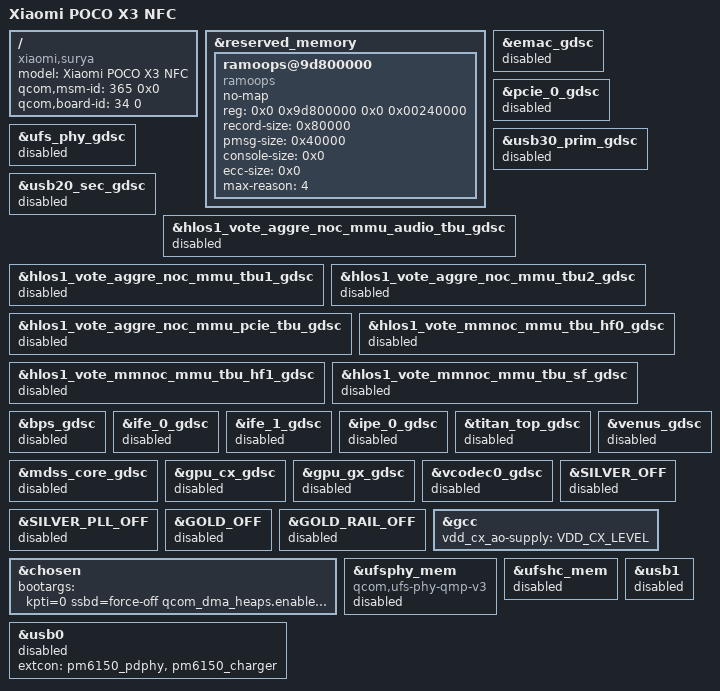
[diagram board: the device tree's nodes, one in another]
// SPDX-License-Identifier: GPL-2.0-only
/dts-v1/;

#include "sm6150.dtsi"
#include "surya-pinctrl.dtsi"
#include "surya-pm6150.dtsi"
#include "surya-display.dtsi"
#include "surya-touch.dtsi"
#include "surya-haptics.dtsi"
#include "surya-nfc.dtsi"

/* Bring-up stub only. Do not flash: inherited platform data is unvalidated. */
/ {
	model = "Xiaomi POCO X3 NFC";
	compatible = "xiaomi,surya", "qcom,sm6150";

	/* IDs from the 4.14 sdmmagpie-idp-overlay-miui.dts. */
	qcom,msm-id = <365 0x0>;
	qcom,board-id = <34 0>;
};

&reserved_memory {
	/*
	 * pstore geometry, derived from what the two kernels that touch this
	 * region actually do -- not guessed.
	 *
	 * Stock 4.14 (arch/arm64/boot/dts/qcom/sdmmagpie.dtsi:669, the DT the
	 * recovery inherits) declares reg = <0x9d800000 0x400000>, record-size
	 * 0x80000, pmsg-size 0x200000, console-size 0x100000, ecc-size 0x10.
	 * Both the 4.14 and the 6.1 ramoops driver lay przs out in one fixed
	 * order -- dmesg, console, ftrace, pmsg -- and give the dmesg set the
	 * whole leftover:
	 *
	 *	dump_mem_sz = mem_size - console - ftrace - pmsg
	 *	cnt         = dump_mem_sz / record-size
	 *	zone_sz     = dump_mem_sz / cnt		(align_down 2)
	 *
	 * so stock resolves to dmesg przs at 0x9d800000 and 0x9d880000 (0x80000
	 * each), console at 0x9d900000, pmsg at 0x9da00000.  The capture lives or
	 * dies on that map, because the recovery reads it and 4.14 destroys what
	 * it does not like (fs/pstore/ram_core.c of that kernel):
	 *
	 *	if (buffer_size(prz) > prz->buffer_size ||
	 *	    buffer_start(prz) > buffer_size(prz))
	 *			pr_info("found existing invalid buffer, ...");
	 *	...
	 *	prz->buffer->sig = sig;
	 *	persistent_ram_zap(prz);		-- the log is gone --
	 *
	 * which is verbatim the report this round: "found existing invalid buffer,
	 * size 57821, start 192977" next to an empty /sys/fs/pstore.
	 *
	 * So the boot console's zone -- 0x9da00000, from
	 * earlycon=ramoops,0x9da00000,0x40000 -- is made the *pmsg* prz, and the
	 * console prz is switched off entirely (console-size 0).  Both halves of
	 * that choice are forced by capture 14 (2026-11-28, console-ramoops-14.txt,
	 * 14225 bytes):
	 *
	 *   1. The same 6.1 kernel boots twice -- once as the kernel under test,
	 *      once as the TWRP kernel that reads the log back.  As a pstore
	 *      *console* owner it logs, 0.227 s into the reading boot:
	 *	[    0.227028] pstore: using zlib compression
	 *	[    0.227539] console [pstore0] enabled
	 *	[    0.227610] ramoops: attached 0x400000@0x9d800000, ecc: 0/0
	 *      (twrp-current-dmesg-9.txt:152-155).  Registering pstore0 untethers
	 *      our earlycon, so the log of the boot under test stops at ~0.227 s;
	 *      and every record the reading boot writes afterwards goes into the
	 *      prz whose header our earlycon owns, rotating the ring we came to
	 *      read.  That is why capture 14 is neither text nor one DEFLATE
	 *      stream: brute-force inflate at every offset (wbits 15/-15/9/-9)
	 *      yields at most 103 bytes of filler, strings -n 14 finds no line,
	 *      and the printable ratio is a flat 38 % from start to end.  A
	 *      capture of somebody else's compressed records, not a silent boot.
	 *   2. The pmsg prz is the only one this driver never writes on its own
	 *      -- /dev/pmsg0 from userspace is its only producer, and recovery
	 *      init never opens it -- so the ring stays exactly as the earlycon
	 *      left it, and both reader families export it (pmsg-ramoops-0, and
	 *      the recovery's own pstore-rw tool).  Earlier rounds already prove
	 *      the path works: pstore-mount-3/4.txt show pmsg-ramoops-0 at 23467
	 *      and 187743 readable bytes while console-ramoops-0 in the same
	 *      directory held 234520 bytes of the *reader's* own log.
	 *
	 * console-size 0 also removes the risk that started this: with two
	 * owners of one 12-byte header, each clamps "size" to its own maximum and
	 * the pair reads start > size -- 192977 is a start the earlycon can never
	 * produce -- and the reader zap()s a zone it calls invalid instead of
	 * exporting it.
	 *
	 * The geometry is unchanged by this, which is the point: solving the two
	 * formulas for a 0x40000 pmsg prz at the end of reg gives mem_size
	 * 0x240000, cnt 4, zone_sz 0x80000, so the dmesg przs still occupy
	 * 0x9d800000..0x9da00000, the pmsg prz is 0x9da00000..0x9da40000 = the
	 * end of reg = the earlycon target, and record-size 0x80000 keeps every
	 * dmesg prz at the size the recovery expects for its own, so a panic
	 * record (dmesg-ramoops-N, deflate, decompressed by this same kernel on
	 * read) survives too.
	 *
	 * ecc-size 0 as well: prz->buffer_size is zone - 12 - ecc
	 * (fs/pstore/ram_core.c:523) while earlycon-ramoops.c uses zone - 12, so
	 * the two owners of one header only agree on capacity without ECC -- and
	 * the reader in the recovery has none either, which its own boot line
	 * states: "ramoops: attached 0x400000@0x9d800000, ecc: 0/0".
	 *
	 * no-map, like the other no-cache regions in this node: a cached alias of
	 * a zone written through ioremap() is a capture that can read back stale.
	 */
	ramoops@9d800000 {
		compatible = "ramoops";
		no-map;
		reg = <0x0 0x9d800000 0x0 0x00240000>;
		record-size = <0x80000>;
		pmsg-size = <0x40000>;
		console-size = <0x0>;
		ecc-size = <0x0>;
		max-reason = <4>;
	};
};

/*
 * The shared SM6150 DT instantiates the 4.14-style vendor gdsc-regulator
 * devices under /soc, but that driver ioremaps the DT reg verbatim while
 * these nodes carry GCC-relative offsets (0x177004 etc.) — so every probe
 * pokes a dead window beside the GCC block.  The first complete boot log
 * (2026-11-27, build 5f716c31f) shows the resulting asynchronous SError
 * landing inside gdsc_probe at 0.33s: readl -> arm_serror_panic -> Kernel
 * panic.  The upstream boot path needs none of them: the 6.1 clock driver
 * owns GDSCs through its C tables, the UFS GDSC is left enabled by the
 * bootloaders exactly as on the stock 4.14 firmware, and the TBU vote
 * nodes have no 6.1 consumer.  Disable the whole family (Violet's own
 * device trees never instantiate it with this driver).
 */
&emac_gdsc { status = "disabled"; };
&pcie_0_gdsc { status = "disabled"; };
&ufs_phy_gdsc { status = "disabled"; };
&usb30_prim_gdsc { status = "disabled"; };
&usb20_sec_gdsc { status = "disabled"; };
&hlos1_vote_aggre_noc_mmu_audio_tbu_gdsc { status = "disabled"; };
&hlos1_vote_aggre_noc_mmu_tbu1_gdsc { status = "disabled"; };
&hlos1_vote_aggre_noc_mmu_tbu2_gdsc { status = "disabled"; };
&hlos1_vote_aggre_noc_mmu_pcie_tbu_gdsc { status = "disabled"; };
&hlos1_vote_mmnoc_mmu_tbu_hf0_gdsc { status = "disabled"; };
&hlos1_vote_mmnoc_mmu_tbu_hf1_gdsc { status = "disabled"; };
&hlos1_vote_mmnoc_mmu_tbu_sf_gdsc { status = "disabled"; };
&bps_gdsc { status = "disabled"; };
&ife_0_gdsc { status = "disabled"; };
&ife_1_gdsc { status = "disabled"; };
&ipe_0_gdsc { status = "disabled"; };
&titan_top_gdsc { status = "disabled"; };
&mdss_core_gdsc { status = "disabled"; };
&gpu_cx_gdsc { status = "disabled"; };
&gpu_gx_gdsc { status = "disabled"; };
&vcodec0_gdsc { status = "disabled"; };
&venus_gdsc { status = "disabled"; };

/*
 * CPU idle states.  This board ships a downstream (4.14-era) PSCI
 * implementation that refuses the OSI-mode switch -- "psci: failed to set PC
 * mode: -3" in every Surya capture -- and has no mapping for the state IDs the
 * inherited DT votes (0x40000003 "pc", 0x40000004 "rail-pc").  The 2026-11-27
 * 20:46 capture shows what that costs: CPU#7 stopped answering IPIs around the
 * first idle entry (~2s), so kick_all_cpus_sync() from the jump-label update
 * spun forever in smp_call_function_many_cond(), RCU never finished a grace
 * period, and init never ran.  Disabling the four CPU states leaves
 * cpuidle-psci with only the WFI state (drivers/cpuidle/dt_idle_states.c skips
 * unavailable states and cpuidle-psci.c adds WFI unconditionally), which is the
 * same idle the stock 4.14 kernel uses until its lpm-levels driver binds.
 * The cluster domain states stay described for the runtime-PM path but are
 * never entered, because no CPU state asks for a cluster power down.
 */
&SILVER_OFF { status = "disabled"; };
&SILVER_PLL_OFF { status = "disabled"; };
&GOLD_OFF { status = "disabled"; };
&GOLD_RAIL_OFF { status = "disabled"; };

/*
 * Boot arguments.  sm6150.dtsi ships fw_devlink.strict=1, which makes every
 * property that lists a phandle a mandatory probe dependency -- including the
 * ones whose supplier is a class device with no driver of its own (see the
 * UFS note below).  fw_devlink=permissive keeps the ordering hints but stops
 * deferring probes on suppliers that can never report "probed", which is how a
 * device tree whose suppliers are class devices (not bound platform drivers) is
 * booted.  loglevel=8 stays because the Surya bring-up markers print at
 * KERN_DEBUG/KERN_NOTICE: at loglevel=7 (the 2026-11-28 21:40 capture) the
 * whole deferral story and the storage snapshot lines were invisible.
 *
 * initcall_debug=1 is dropped as of capture 11.  It is what the last four
 * captures were mined for -- its "probe of af00000.clock-controller returned 0
 * after 6822 usecs" is how dispcc became the control case for GCC -- but one
 * line per initcall and per probe attempt is ~1500 lines, and the 2 MiB
 * console prz then wraps mid-boot: capture 11 came back with two boots
 * byte-interleaved, so the GCC evidence had to be reconstructed instead of
 * read.  gcc_sm6150_probe() now prints one short stage line per step of its
 * own, which is what survives a wrapped buffer, and tools/surya-anykernel no
 *
 * clk_ignore_unused is here because of capture 13, and it is a behaviour knob,
 * not a logging one.  The 6.1 clock framework runs clk_disable_unused() at
 * late_initcall and gates every clock that no driver has claimed, which the
 * downstream 4.14 driver never does: instead of relying on the framework it
 * lists gcc_camera_{ahb,xo}_clk, gcc_disp_{ahb,xo}_clk, gcc_video_{ahb,xo}_clk,
 * gcc_gpu_cfg_ahb_clk, gcc_cpuss_ahb_clk, gcc_cpuss_gnoc_clk and
 * gcc_sys_noc_cpuss_ahb_clk as "critical" and enables them itself
 * (qcom_cc_enable_critical_clks()).  This tree lost that list and kept only the
 * SM8150 register writes that served the same purpose on that SoC -- so by the
 * time the deferred pass reached gcc_sm6150_probe() the AHB path in front of the
 * GCC MISC registers was already gated, and the read that
 * regmap_update_bits(regmap, GCC_CAMERA_MISC, ...) performs first never
 * returned.  Ignoring the unused-clock pass reproduces the 4.14 state for every
 * clock the bootloaders left on, which is the whole point of bring-up here; it
 * also covers the display, camera and GPU register spaces for the same price.
 *
 * softlockup_panic=1 is what makes a capture exist at all.  The detector is
 * already built (CONFIG_SOFTLOCKUP_DETECTOR=y from gki_defconfig) but a report
 * it prints does not stop the boot, so on the boards where a CPU is wedged in a
 * device access init's own 10 s block-device timeout rebooted the phone a few
 * seconds later and the trace either landed in the wrapped tail of the prz or
 * not at all.  With panic the reboot is the *panic* reboot -- warm, so DDR
 * survives -- the buffer ends with "BUG: soft lockup - CPU#N stuck for 22s!"
 * plus that CPU's backtrace, and the collector reads it after.  It also fixes
 * the failure mode seen on 2026-11-28 23:5x, where the boot hung somewhere
 * with no panic and no reboot at all, the user held the power key, and a hard
 * reset drops DDR: /sys/fs/pstore came back empty and the round was lost.
 */
&chosen {
	bootargs = "kpti=0 ssbd=force-off qcom_dma_heaps.enable_bitstream_contig_heap=y rcupdate.rcu_expedited=0 cpufreq.default_governor=performance fw_devlink=permissive cpuidle.off=1 loglevel=8 clk_ignore_unused softlockup_panic=1";
};

/*
 * GCC's CX voltage class.  This is the line that decides whether /soc/ufshc
 * ever probes, and capture 10 (2026-11-28 22:0x, console-ramoops-10.txt)
 * pins it exactly:
 *
 *   1.257457 Surya bringup: r0 probing /soc/clock-controller@100000
 *   1.257865 k61probe: 100000.clock-controller (gcc-sm6150)
 *   ... nothing, ever.  No "Registered GCC clocks", and no
 *   "Rate ... is greater than highest Fmax" line either, so the probe never
 *   reached qcom_cc_really_probe().
 *   5.347050 Surya bringup: provider chain still at /soc/clock-controller@100000
 *   21.475038 Surya bringup: deferred probe still in clock-controller@100000
 *   21.475181 task:kworker/u16:0 state:D ... __mutex_lock+0x408 __device_attach
 *
 * i.e. gcc_sm6150_probe() blocks with the device mutex held, and the serial
 * deferred pass queues behind it.  Before this capture the same probe never
 * even appeared to start, which is why the deferred-probe list looked empty.
 *
 * What it blocks on is the regulator graph, and the DT says why only GCC does:
 * gcc_sm6150_probe() (drivers/clk/qcom/gcc-sm6150.c:3488) makes three
 * mandatory devm_regulator_get() calls and returns the error of each, so an
 * unresolved rail is a probe that cannot finish.  In sm6150-regulator.dtsi the
 * three targets are not peers:
 *
 *   vdd_mx-supply    -> regulator-pm6150-s3           (leaf: no vin/parent edge)
 *   vdd_cx-supply    -> regulator-pm6150-s1          (parent-supply -> s3)
 *   vdd_cx_ao-supply -> regulator-pm6150-s1-level-ao (vin-supply -> s3-level-ao)
 *
 * The AO pair is the odd one out.  Its supplier is the MX AO arc child, whose
 * parent block rpmh-regulator-mxlvl carries no proxy-supply at all (only cxlvl
 * does, which is why the log reports the "Fixed dependency cycle(s)" notice for
 * cxlvl and the VRM LDOs but not for mxlvl), and no driver in this tree except
 * GCC asks for a vdd_cx_ao rail.  dispcc asks for vdd_cx only and its probe
 * returned in 6822 usecs in the same window -- that is the control case: same
 * regulator class, same ARC parent, one supply less, no stall.
 *
 * Capture 11 (2026-11-28) says this was necessary and not sufficient: the
 * property is in the flashed DTB, all three supplies now resolve, and
 * gcc_sm6150_probe() still never returns.  What it is still waiting on is
 * that the regulator *devices* behind these phandles are children of
 * rpmh-regulator-cxlvl/mxlvl and get bound only by the serial deferred pass,
 * which is the pass GCC blocks -- see drivers/base/dd.c, where the chain now
 * names those children explicitly.  This retarget stays because it removes an
 * edge (CX AO to the MX AO arc child) that no other consumer in the tree
 * resolves and that the AO vote does not need on a board that cannot idle.
 *
 * So the AO edge goes away for this board: vote the CX always-on class through
 * the same resolvable pm6150_s1_level regulator the non-AO class uses.  For a
 * level vote that is not a loss of information -- "AO" vs "NAPM" only selects
 * which RPMh TCS the write goes to, i.e. whether AOSD keeps the vote across
 * sleep, and CX is held up through the whole bring-up path (cpuidle.off=1, and
 * this firmware refuses OSI mode anyway: "psci: failed to set PC mode: -3").
 * The clock driver then keeps both classes pointing at one regulator; the core
 * takes the maximum request of the two, which is exactly the corner the
 * bootloader left the rail at.
 */
&gcc {
	vdd_cx_ao-supply = <&VDD_CX_LEVEL>;
};

/*
 * UFS host and PHY.  The 4.14 supply routing is deliberately NOT inherited.
 * Each *-supply here names an LDO child of a qcom,rpmh-vrm-regulator parent,
 * and the vendor rpmh-regulator driver registers those LDOs with
 * devm_regulator_register(): the regulator struct device carries the child
 * node as of_node but never becomes the primary fwnode device of that node,
 * so the fw_devlink link from the UFS nodes has no supplier device to wait
 * on and the consumer is parked without a single log line.  That is the exact
 * shape of the 2026-11-27 20:46 failure: "/soc/ufshc@1d84000 enabled;
 * unbound" and "/soc/ufsphy_mem@1d87000 enabled; unbound" at 4.58s with an
 * empty deferred-probe list, so no block device ever appeared for
 * first-stage init.
 *
 * Both drivers take an absent supply as "rail is already up": ufshcd does it
 * explicitly ("Unable to find %s regulator, assuming enabled"), ufs-qcom only
 * parses qcom,vddp-ref-clk when the property exists, and the QMP v3 PHY driver
 * never asks for vdda-phy/vdda-pll at all.  The rails must stay as the
 * bootloaders left them -- the boot device hangs off VCC/VCCQ2 -- so dropping
 * the phandles is both the unblock and the honest description of the boot
 * state.  Same reasoning as the removed vdd-hba-supply.
 */
&ufsphy_mem {
	/*
	 * "qcom,ufs-phy-qmp-v3", because that is the string stock uses for this
	 * silicon: arch/arm64/boot/dts/qcom/sdmmagpie.dtsi of the 4.14 source -- the
	 * kernel that boots this board off UFS today -- gives &ufsphy_mem exactly
	 * that compatible, and drivers/phy/qualcomm/phy-qcom-ufs-qmp-v4.c carries a
	 * different PHY revision's calibration.  Counting the {register, value}
	 * pairs of the tables says the same thing: stock's phy-qcom-ufs-qmp-v3.h has
	 * 88, this tree's phy-qcom-ufs-qmp-v3.h reproduces all 88,
	 * phy-qcom-ufs-qmp-v4.h 33 and phy-qcom-ufs-qmp-v3-660.h 27.  Binding V4
	 * meant two thirds of the QSERDES/PA trim registers were written for another
	 * PHY -- a link that never trains, which is the silence this board keeps
	 * producing.
	 *
	 * An earlier round put "qcom,ufs-phy-qmp-v4" here for a defensible but
	 * wrong reason: capture 13 showed the node "enabled; unbound" with
	 * "can_match: 0", and no *built* driver matched "qcom,ufs-phy-qmp-v3" --
	 * because in this tree that file sits behind CONFIG_PHY_QCOM_UFS_V3_SM4350,
	 * whose Kconfig prompt ("UFS Holi Phy Driver") names the board that shipped
	 * with it, not the PHY it drives.  The right move was to enable the symbol,
	 * which arch/arm64/configs/vendor/surya.config now does; picking a driver
	 * whose table does not match the silicon was not.  The workflow gate now
	 * checks the compatible against the of_match tables of the drivers actually
	 * built, so the label cannot outvote the hardware again.
	 *
	 * Nothing else about the node changes.  reg-names = "phy_mem" feeds
	 * platform_get_resource_byname(), #phy-cells = <0> is what the host's
	 * of_phy_simple_xlate() needs, clock-names = "ref_clk_src", "ref_clk",
	 * "ref_aux_clk" are the three ufs_qcom_phy_init_clks() looks up from
	 * .init, "tx_iface_clk"/"rx_iface_clk" stay optional, and resets =
	 * <&ufshc_mem 0> is acquired by this driver's init path.  The vdda-phy and
	 * vdda-pll supplies remain absent on purpose: the vendor rpmh-regulator
	 * registers those LDOs without making the child node its primary fwnode
	 * device, so a phandle here parks the consumer silently (see the note on
	 * &ufshc_mem); the -ENODATA tolerance in drivers/phy/qualcomm/phy-qcom-ufs.c
	 * is what lets the driver treat "no supply" as "rail already up".
	 */
	compatible = "qcom,ufs-phy-qmp-v3";
	status = "disabled";
};

&ufshc_mem {
	/* Stock SDMMagpie uses the dedicated UFS_RESET pin, not GPIO 123. */
	/delete-property/ reset-gpios;
	/* Stock Surya UFS does not use the SM6150 boot fuse gate. */
	/delete-property/ nvmem-cells;
	/delete-property/ nvmem-cell-names;
	/delete-property/ boot_device_type;
	status = "disabled";
};

/* USB role detection requires the Surya PMIC and Type-C policy nodes. */
&usb0 {
	extcon = <&pm6150_pdphy>, <&pm6150_charger>;
	status = "disabled";
};

&usb1 {
	status = "disabled";
};
